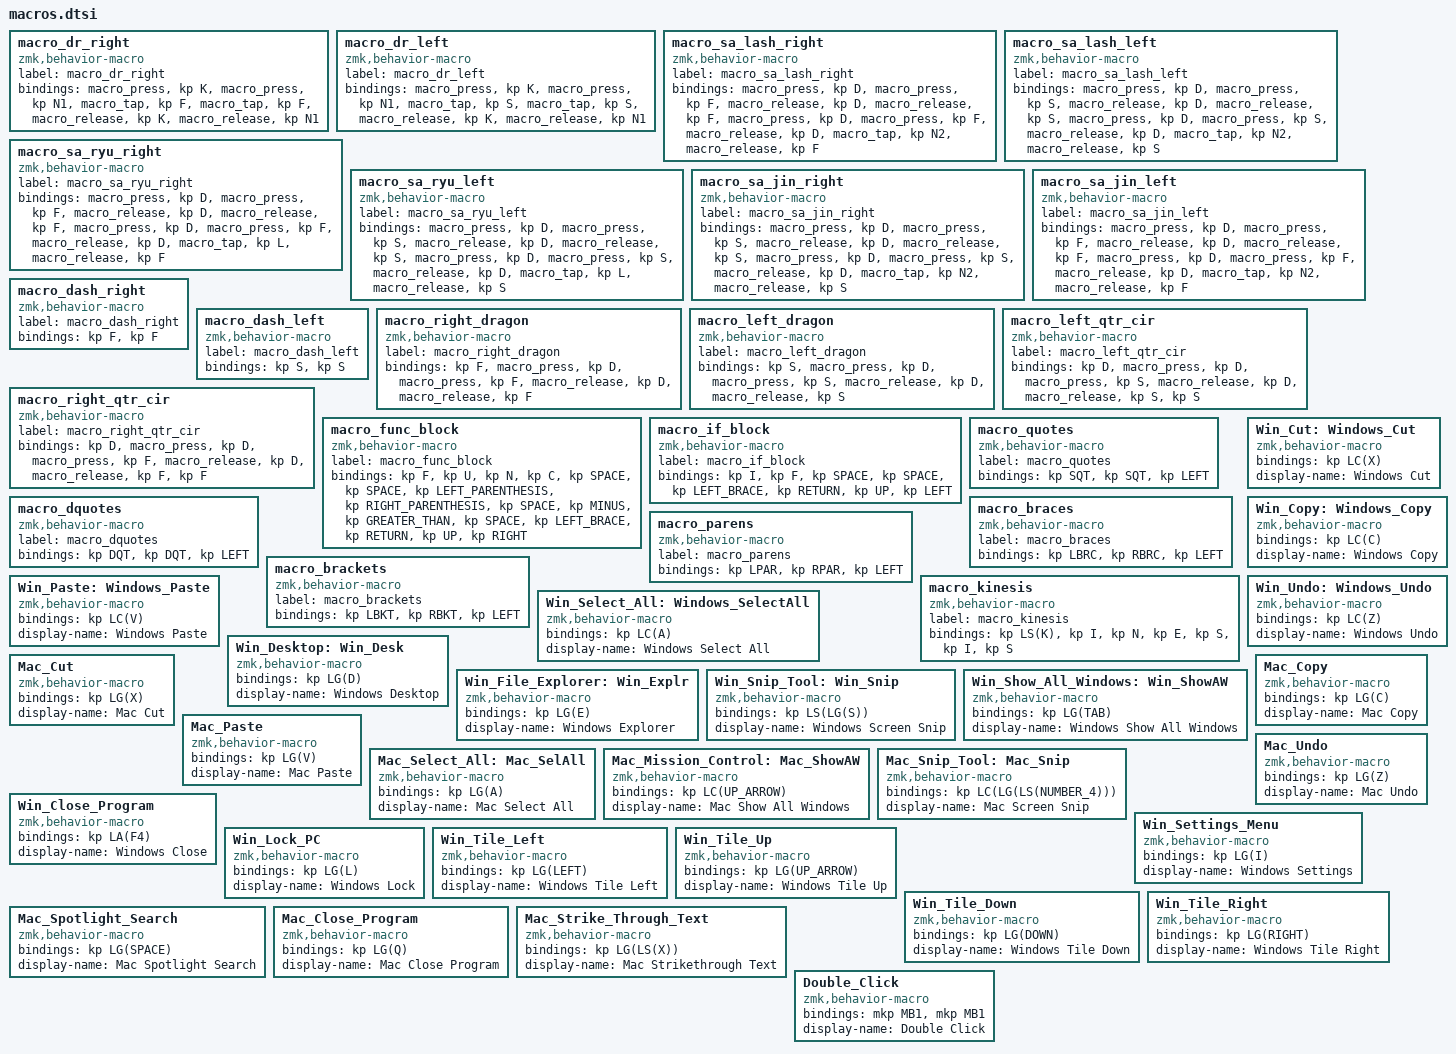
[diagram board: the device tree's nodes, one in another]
macro_dr_right: macro_dr_right{
compatible = "zmk,behavior-macro";
label = "macro_dr_right";
#binding-cells = <0>;
bindings = <&macro_press &kp K>, <&macro_press &kp N1>, <&macro_tap &kp F>, <&macro_tap &kp F>, <&macro_release &kp K>, <&macro_release &kp N1>;
};
macro_dr_left: macro_dr_left{
compatible = "zmk,behavior-macro";
label = "macro_dr_left";
#binding-cells = <0>;
bindings = <&macro_press &kp K>, <&macro_press &kp N1>, <&macro_tap &kp S>, <&macro_tap &kp S>, <&macro_release &kp K>, <&macro_release &kp N1>;
};
macro_sa_lash_right: macro_sa_lash_right{
compatible = "zmk,behavior-macro";
label = "macro_sa_lash_right";
#binding-cells = <0>;
bindings = <&macro_press &kp D>, <&macro_press &kp F>, <&macro_release &kp D>, <&macro_release &kp F>, <&macro_press &kp D>, <&macro_press &kp F>, <&macro_release &kp D>, <&macro_tap &kp N2>, <&macro_release &kp F>;
};
macro_sa_lash_left: macro_sa_lash_left{
compatible = "zmk,behavior-macro";
label = "macro_sa_lash_left";
#binding-cells = <0>;
bindings = <&macro_press &kp D>, <&macro_press &kp S>, <&macro_release &kp D>, <&macro_release &kp S>, <&macro_press &kp D>, <&macro_press &kp S>, <&macro_release &kp D>, <&macro_tap &kp N2>, <&macro_release &kp S>;
};
macro_sa_ryu_right: macro_sa_ryu_right{
compatible = "zmk,behavior-macro";
label = "macro_sa_ryu_right";
#binding-cells = <0>;
bindings = <&macro_press &kp D>, <&macro_press &kp F>, <&macro_release &kp D>, <&macro_release &kp F>, <&macro_press &kp D>, <&macro_press &kp F>, <&macro_release &kp D>, <&macro_tap &kp L>, <&macro_release &kp F>;
};
macro_sa_ryu_left: macro_sa_ryu_left{
compatible = "zmk,behavior-macro";
label = "macro_sa_ryu_left";
#binding-cells = <0>;
bindings = <&macro_press &kp D>, <&macro_press &kp S>, <&macro_release &kp D>, <&macro_release &kp S>, <&macro_press &kp D>, <&macro_press &kp S>, <&macro_release &kp D>, <&macro_tap &kp L>, <&macro_release &kp S>;
};
macro_sa_jin_right: macro_sa_jin_right{
compatible = "zmk,behavior-macro";
label = "macro_sa_jin_right";
#binding-cells = <0>;
bindings = <&macro_press &kp D>, <&macro_press &kp S>, <&macro_release &kp D>, <&macro_release &kp S>, <&macro_press &kp D>, <&macro_press &kp S>, <&macro_release &kp D>, <&macro_tap &kp N2>, <&macro_release &kp S>;
};
macro_sa_jin_left: macro_sa_jin_left{
compatible = "zmk,behavior-macro";
label = "macro_sa_jin_left";
#binding-cells = <0>;
bindings = <&macro_press &kp D>, <&macro_press &kp F>, <&macro_release &kp D>, <&macro_release &kp F>, <&macro_press &kp D>, <&macro_press &kp F>, <&macro_release &kp D>, <&macro_tap &kp N2>, <&macro_release &kp F>;
};
macro_dash_right: macro_dash_right{
compatible = "zmk,behavior-macro";
label = "macro_dash_right";
#binding-cells = <0>;
bindings = <&kp F>, <&kp F>;
};
macro_dash_left: macro_dash_left{
compatible = "zmk,behavior-macro";
label = "macro_dash_left";
#binding-cells = <0>;
bindings = <&kp S>, <&kp S>;
};
macro_right_dragon: macro_right_dragon{
compatible = "zmk,behavior-macro";
label = "macro_right_dragon";
#binding-cells = <0>;
bindings = <&kp F>, <&macro_press &kp D>, <&macro_press &kp F>, <&macro_release &kp D>, <&macro_release &kp F>;
};
macro_left_dragon: macro_left_dragon{
compatible = "zmk,behavior-macro";
label = "macro_left_dragon";
#binding-cells = <0>;
bindings = <&kp S>, <&macro_press &kp D>, <&macro_press &kp S>, <&macro_release &kp D>, <&macro_release &kp S>;
};
macro_left_qtr_cir: macro_left_qtr_cir{
compatible = "zmk,behavior-macro";
label = "macro_left_qtr_cir";
#binding-cells = <0>;
bindings = <&kp D>, <&macro_press &kp D>, <&macro_press &kp S>, <&macro_release &kp D>, <&macro_release &kp S>, <&kp S>;
};
macro_right_qtr_cir: macro_right_qtr_cir{
compatible = "zmk,behavior-macro";
label = "macro_right_qtr_cir";
#binding-cells = <0>;
bindings = <&kp D>, <&macro_press &kp D>, <&macro_press &kp F>, <&macro_release &kp D>, <&macro_release &kp F>, <&kp F>;
};
macro_func_block: macro_func_block{
compatible = "zmk,behavior-macro";
label = "macro_func_block";
#binding-cells = <0>;
bindings = <&kp F>, <&kp U>, <&kp N>, <&kp C>, <&kp SPACE>, <&kp SPACE>, <&kp LEFT_PARENTHESIS>, <&kp RIGHT_PARENTHESIS>, <&kp SPACE>, <&kp MINUS>, <&kp GREATER_THAN>, <&kp SPACE>, <&kp LEFT_BRACE>, <&kp RETURN>, <&kp UP>, <&kp RIGHT>;
};
macro_if_block: macro_if_block{
compatible = "zmk,behavior-macro";
label = "macro_if_block";
#binding-cells = <0>;
bindings = <&kp I>, <&kp F>, <&kp SPACE>, <&kp SPACE>, <&kp LEFT_BRACE>, <&kp RETURN>, <&kp UP>, <&kp LEFT>;
};
macro_quotes: macro_quotes{
compatible = "zmk,behavior-macro";
label = "macro_quotes";
#binding-cells = <0>;
bindings = <&kp SQT>, <&kp SQT>, <&kp LEFT>;
};
macro_dquotes: macro_dquotes{
compatible = "zmk,behavior-macro";
label = "macro_dquotes";
#binding-cells = <0>;
bindings = <&kp DQT>, <&kp DQT>, <&kp LEFT>;
};
macro_braces: macro_braces{
compatible = "zmk,behavior-macro";
label = "macro_braces";
#binding-cells = <0>;
bindings = <&kp LBRC>, <&kp RBRC>, <&kp LEFT>;
};
macro_parens: macro_parens{
compatible = "zmk,behavior-macro";
label = "macro_parens";
#binding-cells = <0>;
bindings = <&kp LPAR>, <&kp RPAR>, <&kp LEFT>;
};
macro_brackets: macro_brackets{
compatible = "zmk,behavior-macro";
label = "macro_brackets";
#binding-cells = <0>;
bindings = <&kp LBKT>, <&kp RBKT>, <&kp LEFT>;
};
  macro_kinesis: macro_kinesis {
    compatible = "zmk,behavior-macro";
    label = "macro_kinesis";
    #binding-cells = <0>;
    bindings = <&kp LS(K)>, <&kp I>, <&kp N>, <&kp E>, <&kp S>, <&kp I>, <&kp S>;
  };
  Win_Cut: Windows_Cut {
    compatible = "zmk,behavior-macro";
    #binding-cells = <0>;
    bindings = <&kp LC(X)>;
    display-name = "Windows Cut";
  };

  Win_Copy: Windows_Copy {
    compatible = "zmk,behavior-macro";
    #binding-cells = <0>;
    bindings = <&kp LC(C)>;
    display-name = "Windows Copy";
  };

  Win_Paste: Windows_Paste {
    compatible = "zmk,behavior-macro";
    #binding-cells = <0>;
    bindings = <&kp LC(V)>;
    display-name = "Windows Paste";
  };

  Win_Select_All: Windows_SelectAll {
      compatible = "zmk,behavior-macro";
      #binding-cells = <0>;
      bindings = <&kp LC(A)>;
      display-name = "Windows Select All";
  };

  Win_Undo: Windows_Undo {
    compatible = "zmk,behavior-macro";
    #binding-cells = <0>;
    bindings = <&kp LC(Z)>;
    display-name = "Windows Undo";
  };

  Win_Desktop: Win_Desk {
    compatible = "zmk,behavior-macro";
    #binding-cells = <0>;
    bindings = <&kp LG(D)>;
    display-name = "Windows Desktop";
  };

  Win_File_Explorer: Win_Explr {
    compatible = "zmk,behavior-macro";
    #binding-cells = <0>;
    bindings = <&kp LG(E)>;
    display-name = "Windows Explorer";
  };

  Win_Snip_Tool: Win_Snip {
    compatible = "zmk,behavior-macro";
    #binding-cells = <0>;
    bindings = <&kp LS(LG(S))>;
    display-name = "Windows Screen Snip";
  };

  Win_Show_All_Windows: Win_ShowAW {
    compatible = "zmk,behavior-macro";
    #binding-cells = <0>;
    bindings = <&kp LG(TAB)>;
    display-name = "Windows Show All Windows";
  };

  Mac_Cut: Mac_Cut {
    compatible = "zmk,behavior-macro";
    #binding-cells = <0>;
    bindings = <&kp LG(X)>;
    display-name = "Mac Cut";
  };

  Mac_Copy: Mac_Copy {
    compatible = "zmk,behavior-macro";
    #binding-cells = <0>;
    bindings = <&kp LG(C)>;
    display-name = "Mac Copy";
  };

  Mac_Paste: Mac_Paste {
    compatible = "zmk,behavior-macro";
    #binding-cells = <0>;
    bindings = <&kp LG(V)>;
    display-name = "Mac Paste";
  };

  Mac_Undo: Mac_Undo {
    compatible = "zmk,behavior-macro";
    #binding-cells = <0>;
    bindings = <&kp LG(Z)>;
    display-name = "Mac Undo";
  };

  Mac_Select_All: Mac_SelAll {
    compatible = "zmk,behavior-macro";
    #binding-cells = <0>;
    bindings = <&kp LG(A)>;
    display-name = "Mac Select All";
  };

  Mac_Mission_Control: Mac_ShowAW {
    compatible = "zmk,behavior-macro";
    #binding-cells = <0>;
    bindings = <&kp LC(UP_ARROW)>;
    display-name = "Mac Show All Windows";
  };

  Mac_Snip_Tool: Mac_Snip {
    compatible = "zmk,behavior-macro";
    #binding-cells = <0>;
    bindings = <&kp LC(LG(LS(NUMBER_4)))>;
    display-name = "Mac Screen Snip";
  };

  Win_Close_Program: Win_Close_Program {
    compatible = "zmk,behavior-macro";
    #binding-cells = <0>;
    bindings = <&kp LA(F4)>;
    display-name = "Windows Close";
  };

  Win_Settings_Menu: Win_Settings_Menu {
    compatible = "zmk,behavior-macro";
    #binding-cells = <0>;
    bindings = <&kp LG(I)>;
    display-name = "Windows Settings";
  };

  Win_Lock_PC: Win_Lock_PC {
    compatible = "zmk,behavior-macro";
    #binding-cells = <0>;
    bindings = <&kp LG(L)>;
    display-name = "Windows Lock";
  };

  Win_Tile_Left: Win_Tile_Left {
    compatible = "zmk,behavior-macro";
    #binding-cells = <0>;
    bindings = <&kp LG(LEFT)>;
    display-name = "Windows Tile Left";
  };

  Win_Tile_Up: Win_Tile_Up {
    compatible = "zmk,behavior-macro";
    #binding-cells = <0>;
    bindings = <&kp LG(UP_ARROW)>;
    display-name = "Windows Tile Up";
  };

  Win_Tile_Down: Win_Tile_Down {
    compatible = "zmk,behavior-macro";
    #binding-cells = <0>;
    bindings = <&kp LG(DOWN)>;
    display-name = "Windows Tile Down";
  };

  Win_Tile_Right: Win_Tile_Right {
    compatible = "zmk,behavior-macro";
    #binding-cells = <0>;
    bindings = <&kp LG(RIGHT)>;
    display-name = "Windows Tile Right";
  };

  Mac_Spotlight_Search: Mac_Spotlight_Search {
    compatible = "zmk,behavior-macro";
    #binding-cells = <0>;
    bindings = <&kp LG(SPACE)>;
    display-name = "Mac Spotlight Search";
  };

  Mac_Close_Program: Mac_Close_Program {
    compatible = "zmk,behavior-macro";
    #binding-cells = <0>;
    bindings = <&kp LG(Q)>;
    display-name = "Mac Close Program";
  };

  Mac_Strike_Through_Text: Mac_Strike_Through_Text {
    compatible = "zmk,behavior-macro";
    #binding-cells = <0>;
    bindings = <&kp LG(LS(X))>;
    display-name = "Mac Strikethrough Text";
  };

  Double_Click: Double_Click {
    compatible = "zmk,behavior-macro";
    #binding-cells = <0>;
    bindings = <&mkp MB1 &mkp MB1>;
    display-name = "Double Click";
  };
